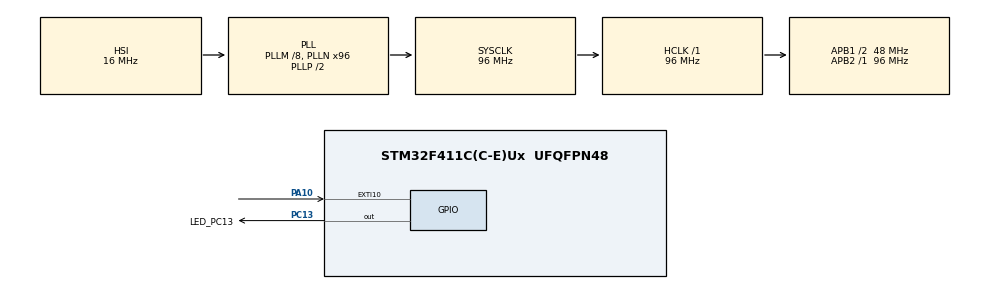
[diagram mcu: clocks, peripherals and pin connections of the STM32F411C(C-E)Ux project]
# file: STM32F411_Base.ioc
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Mcu.Family=STM32F4
Mcu.Name=STM32F411C(C-E)Ux
Mcu.Package=UFQFPN48
NVIC.EXTI15_10_IRQn=true\:0\:0\:false\:false\:true\:true\:true\:true
NVIC.PriorityGroup=NVIC_PRIORITYGROUP_4
PA10.GPIO_PuPd=GPIO_PULLDOWN
PA10.Signal=GPXTI10
PA13.Mode=Serial_Wire
PA13.Signal=SYS_JTMS-SWDIO
PA14.Mode=Serial_Wire
PA14.Signal=SYS_JTCK-SWCLK
PC13-ANTI_TAMP.GPIO_Label=LED_PC13
PC13-ANTI_TAMP.Signal=GPIO_Output
ProjectManager.HeapSize=0x200
ProjectManager.StackSize=0x400
ProjectManager.TargetToolchain=CMake
RCC.48MHZClocksFreq_Value=48000000
RCC.AHBFreq_Value=96000000
RCC.APB1CLKDivider=RCC_HCLK_DIV2
RCC.APB1Freq_Value=48000000
RCC.APB1TimFreq_Value=96000000
RCC.APB2Freq_Value=96000000
RCC.APB2TimFreq_Value=96000000
RCC.CortexFreq_Value=96000000
RCC.HCLKFreq_Value=96000000
RCC.HSE_VALUE=25000000
RCC.HSI_VALUE=16000000
RCC.LSE_VALUE=32768
RCC.PLLM=8
RCC.PLLN=96
RCC.SYSCLKFreq_VALUE=96000000
RCC.SYSCLKSource=RCC_SYSCLKSOURCE_PLLCLK
RCC.VCOOutputFreq_Value=192000000
board=custom

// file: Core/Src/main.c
/* USER CODE BEGIN Header */
/**
  ******************************************************************************
  * @file           : main.c
  * @brief          : Main program body
  ******************************************************************************
  * @attention
  *
  * Copyright (c) 2026 STMicroelectronics.
  * All rights reserved.
  *
  * This software is licensed under terms that can be found in the LICENSE file
  * in the root directory of this software component.
  * If no LICENSE file comes with this software, it is provided AS-IS.
  *
  ******************************************************************************
  */
/* USER CODE END Header */
#include "main.h"

void SystemClock_Config(void);
static void MX_GPIO_Init(void);

/* USER CODE BEGIN 0 */
void HAL_GPIO_EXTI_Callback(uint16_t GPIO_Pin)
{
    if (GPIO_Pin == GPIO_PIN_10)
    {
        HAL_GPIO_TogglePin(GPIOC, GPIO_PIN_13); // đảo trạng thái LED
    }
}
/* USER CODE END 0 */

int main(void)
{

  /* MCU Configuration--------------------------------------------------------*/

  /* Reset of all peripherals, Initializes the Flash interface and the Systick. */
  HAL_Init();

  /* Configure the system clock */
  SystemClock_Config();

  /* Initialize all configured peripherals */
  MX_GPIO_Init();

  /* Infinite loop */
  while (1)
  {

    /* USER CODE BEGIN 3 */
    // HAL_GPIO_TogglePin(GPIOA, GPIO_PIN_10);
    // HAL_Delay(500);
  }
  /* USER CODE END 3 */
}

void SystemClock_Config(void)
{
  RCC_OscInitTypeDef RCC_OscInitStruct = {0};
  RCC_ClkInitTypeDef RCC_ClkInitStruct = {0};

  /** Configure the main internal regulator output voltage
  */
  __HAL_RCC_PWR_CLK_ENABLE();
  __HAL_PWR_VOLTAGESCALING_CONFIG(PWR_REGULATOR_VOLTAGE_SCALE1);

  /** Initializes the RCC Oscillators according to the specified parameters
  * in the RCC_OscInitTypeDef structure.
  */
  RCC_OscInitStruct.OscillatorType = RCC_OSCILLATORTYPE_HSI;
  RCC_OscInitStruct.HSIState = RCC_HSI_ON;
  RCC_OscInitStruct.HSICalibrationValue = RCC_HSICALIBRATION_DEFAULT;
  RCC_OscInitStruct.PLL.PLLState = RCC_PLL_ON;
  RCC_OscInitStruct.PLL.PLLSource = RCC_PLLSOURCE_HSI;
  RCC_OscInitStruct.PLL.PLLM = 8;
  RCC_OscInitStruct.PLL.PLLN = 96;
  RCC_OscInitStruct.PLL.PLLP = RCC_PLLP_DIV2;
  RCC_OscInitStruct.PLL.PLLQ = 4;
  if (HAL_RCC_OscConfig(&RCC_OscInitStruct) != HAL_OK)
  {
    Error_Handler();
  }

  /** Initializes the CPU, AHB and APB buses clocks
  */
  RCC_ClkInitStruct.ClockType = RCC_CLOCKTYPE_HCLK|RCC_CLOCKTYPE_SYSCLK
                              |RCC_CLOCKTYPE_PCLK1|RCC_CLOCKTYPE_PCLK2;
  RCC_ClkInitStruct.SYSCLKSource = RCC_SYSCLKSOURCE_PLLCLK;
  RCC_ClkInitStruct.AHBCLKDivider = RCC_SYSCLK_DIV1;
  RCC_ClkInitStruct.APB1CLKDivider = RCC_HCLK_DIV2;
  RCC_ClkInitStruct.APB2CLKDivider = RCC_HCLK_DIV1;

  if (HAL_RCC_ClockConfig(&RCC_ClkInitStruct, FLASH_LATENCY_3) != HAL_OK)
  {
    Error_Handler();
  }
}

static void MX_GPIO_Init(void)
{
  GPIO_InitTypeDef GPIO_InitStruct = {0};

  /* GPIO Ports Clock Enable */
  __HAL_RCC_GPIOC_CLK_ENABLE();
  __HAL_RCC_GPIOA_CLK_ENABLE();

  /*Configure GPIO pin Output Level */
  HAL_GPIO_WritePin(LED_PC13_GPIO_Port, LED_PC13_Pin, GPIO_PIN_RESET);

  /*Configure GPIO pin : LED_PC13_Pin */
  GPIO_InitStruct.Pin = LED_PC13_Pin;
  GPIO_InitStruct.Mode = GPIO_MODE_OUTPUT_PP;
  GPIO_InitStruct.Pull = GPIO_NOPULL;
  GPIO_InitStruct.Speed = GPIO_SPEED_FREQ_LOW;
  HAL_GPIO_Init(LED_PC13_GPIO_Port, &GPIO_InitStruct);

  /*Configure GPIO pin : PA10 */
  GPIO_InitStruct.Pin = GPIO_PIN_10;
  GPIO_InitStruct.Mode = GPIO_MODE_IT_RISING;
  GPIO_InitStruct.Pull = GPIO_PULLDOWN;
  HAL_GPIO_Init(GPIOA, &GPIO_InitStruct);

  /* EXTI interrupt init*/
  HAL_NVIC_SetPriority(EXTI15_10_IRQn, 0, 0);
  HAL_NVIC_EnableIRQ(EXTI15_10_IRQn);

}

void Error_Handler(void)
{
  __disable_irq();
  while (1)
  {
  }
}
